# CY8C5868AXI_LP035 register map
File version: 0.1
Registers are 8-bit, read-write, no defined reset value unless marked. A register's access mark holds for its fields unless they carry their own. Offsets are from the block's base; [hi:lo] are bit positions; 'fields as' and 'values as' point back to an identical list.

## HORIZ
Base 0x00000000
0x4000642B HORIZ__COMPARE1 — UDB.D0 - Assigned Compare1 Value
0x4000643B HORIZ__COMPARE2 — UDB.D1 - Assigned Compare2 Value
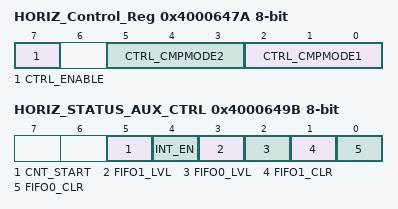
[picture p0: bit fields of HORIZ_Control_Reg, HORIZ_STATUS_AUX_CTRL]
0x4000647A HORIZ_Control_Reg — UDB Control Register - Assigned Control Register Value
  [7] CTRL_ENABLE — Enable the PWM
  [5:3] CTRL_CMPMODE2 — Compare mode 2
  [2:0] CTRL_CMPMODE1 — Compare mode 1
0x4000649B HORIZ_STATUS_AUX_CTRL — UDB Auxilliary Control Register
  [5] CNT_START — FIFO0 clear
    0=E_CNT_START0 (Disable counter); 1=E_CNT_START1 (Enable counter)
  [4] INT_EN
    0=E_INT_EN0 (Interrupt disabled); 1=E_INT_EN1 (Interrupt enabled)
  [3] FIFO1_LVL — FIFO level
    0=E_FIFO_LVL_0 (FIFO LVL: input mode: FIFO not full; output mode: FIFO not empty); 1=E_FIFO_LVL_1 (FIFO LVL: input mode: FIFO at least 1/2 empty; output mode: FIFO at least 1/2 full)
  [2] FIFO0_LVL — FIFO level
    values as FIFO1_LVL
  [1] FIFO1_CLR — FIFO1 clear
    0=E_FIFO_CLR_0 (Normal FIFO operation); 1=E_FIFO_CLR_1 (Clear FIFO state)
  [0] FIFO0_CLR — FIFO0 clear
    values as FIFO1_CLR

## VERT
Base 0x00000000
0x4000652A VERT_COMPARE_Reg 16-bit — UDB.D0 - Assigned Compare Value
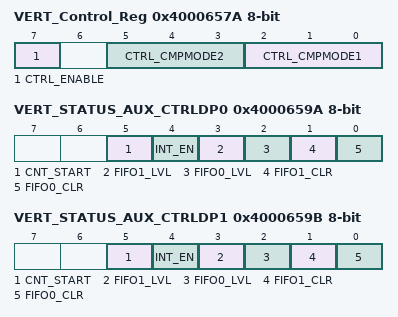
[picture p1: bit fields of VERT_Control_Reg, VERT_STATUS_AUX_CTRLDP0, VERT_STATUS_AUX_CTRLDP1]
0x4000657A VERT_Control_Reg — UDB Control Register - Assigned Control Register Value
  [7] CTRL_ENABLE — Enable the PWM
  [5:3] CTRL_CMPMODE2 — Compare mode 2
  [2:0] CTRL_CMPMODE1 — Compare mode 1
0x4000659A VERT_STATUS_AUX_CTRLDP0 — UDB Auxilliary Control Register
  [5] CNT_START — FIFO0 clear
    0=E_CNT_START0 (Disable counter); 1=E_CNT_START1 (Enable counter)
  [4] INT_EN
    0=E_INT_EN0 (Interrupt disabled); 1=E_INT_EN1 (Interrupt enabled)
  [3] FIFO1_LVL — FIFO level
    0=E_FIFO_LVL_0 (FIFO LVL: input mode: FIFO not full; output mode: FIFO not empty); 1=E_FIFO_LVL_1 (FIFO LVL: input mode: FIFO at least 1/2 empty; output mode: FIFO at least 1/2 full)
  [2] FIFO0_LVL — FIFO level
    values as FIFO1_LVL
  [1] FIFO1_CLR — FIFO1 clear
    0=E_FIFO_CLR_0 (Normal FIFO operation); 1=E_FIFO_CLR_1 (Clear FIFO state)
  [0] FIFO0_CLR — FIFO0 clear
    values as FIFO1_CLR
0x4000659B VERT_STATUS_AUX_CTRLDP1 — UDB Auxilliary Control Register
  fields as VERT_STATUS_AUX_CTRLDP0

## HSYNC
Base 0x00000000
0x40006428 HSYNC_COMPARE_Reg_ — UDB.D0 - Assigned Compare Value
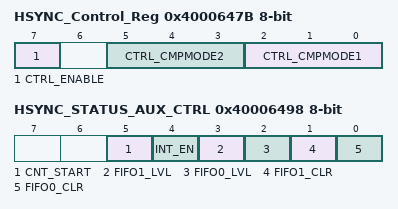
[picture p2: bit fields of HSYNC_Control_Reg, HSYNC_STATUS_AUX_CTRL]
0x4000647B HSYNC_Control_Reg — UDB Control Register - Assigned Control Register Value
  [7] CTRL_ENABLE — Enable the PWM
  [5:3] CTRL_CMPMODE2 — Compare mode 2
  [2:0] CTRL_CMPMODE1 — Compare mode 1
0x40006498 HSYNC_STATUS_AUX_CTRL — UDB Auxilliary Control Register
  [5] CNT_START — FIFO0 clear
    0=E_CNT_START0 (Disable counter); 1=E_CNT_START1 (Enable counter)
  [4] INT_EN
    0=E_INT_EN0 (Interrupt disabled); 1=E_INT_EN1 (Interrupt enabled)
  [3] FIFO1_LVL — FIFO level
    0=E_FIFO_LVL_0 (FIFO LVL: input mode: FIFO not full; output mode: FIFO not empty); 1=E_FIFO_LVL_1 (FIFO LVL: input mode: FIFO at least 1/2 empty; output mode: FIFO at least 1/2 full)
  [2] FIFO0_LVL — FIFO level
    values as FIFO1_LVL
  [1] FIFO1_CLR — FIFO1 clear
    0=E_FIFO_CLR_0 (Normal FIFO operation); 1=E_FIFO_CLR_1 (Clear FIFO state)
  [0] FIFO0_CLR — FIFO0 clear
    values as FIFO1_CLR

## VSYNC
Base 0x00000000
0x40006528 VSYNC_COMPARE_Reg_ — UDB.D0 - Assigned Compare Value
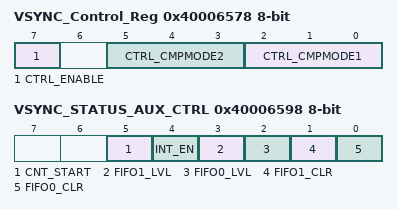
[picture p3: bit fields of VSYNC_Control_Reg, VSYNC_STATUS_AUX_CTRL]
0x40006578 VSYNC_Control_Reg — UDB Control Register - Assigned Control Register Value
  [7] CTRL_ENABLE — Enable the PWM
  [5:3] CTRL_CMPMODE2 — Compare mode 2
  [2:0] CTRL_CMPMODE1 — Compare mode 1
0x40006598 VSYNC_STATUS_AUX_CTRL — UDB Auxilliary Control Register
  [5] CNT_START — FIFO0 clear
    0=E_CNT_START0 (Disable counter); 1=E_CNT_START1 (Enable counter)
  [4] INT_EN
    0=E_INT_EN0 (Interrupt disabled); 1=E_INT_EN1 (Interrupt enabled)
  [3] FIFO1_LVL — FIFO level
    0=E_FIFO_LVL_0 (FIFO LVL: input mode: FIFO not full; output mode: FIFO not empty); 1=E_FIFO_LVL_1 (FIFO LVL: input mode: FIFO at least 1/2 empty; output mode: FIFO at least 1/2 full)
  [2] FIFO0_LVL — FIFO level
    values as FIFO1_LVL
  [1] FIFO1_CLR — FIFO1 clear
    0=E_FIFO_CLR_0 (Normal FIFO operation); 1=E_FIFO_CLR_1 (Clear FIFO state)
  [0] FIFO0_CLR — FIFO0 clear
    values as FIFO1_CLR
